AUTOSAR XML (schema 4-0-3)
standard types defined: Boolean, UInt16
package /AUTOSAR_Platform/DataConstrs
  range DC_Boolean: raw 0..1
  range DC_UInt16: raw 0..65535
package /PATAC/MSM/ComponentTypes
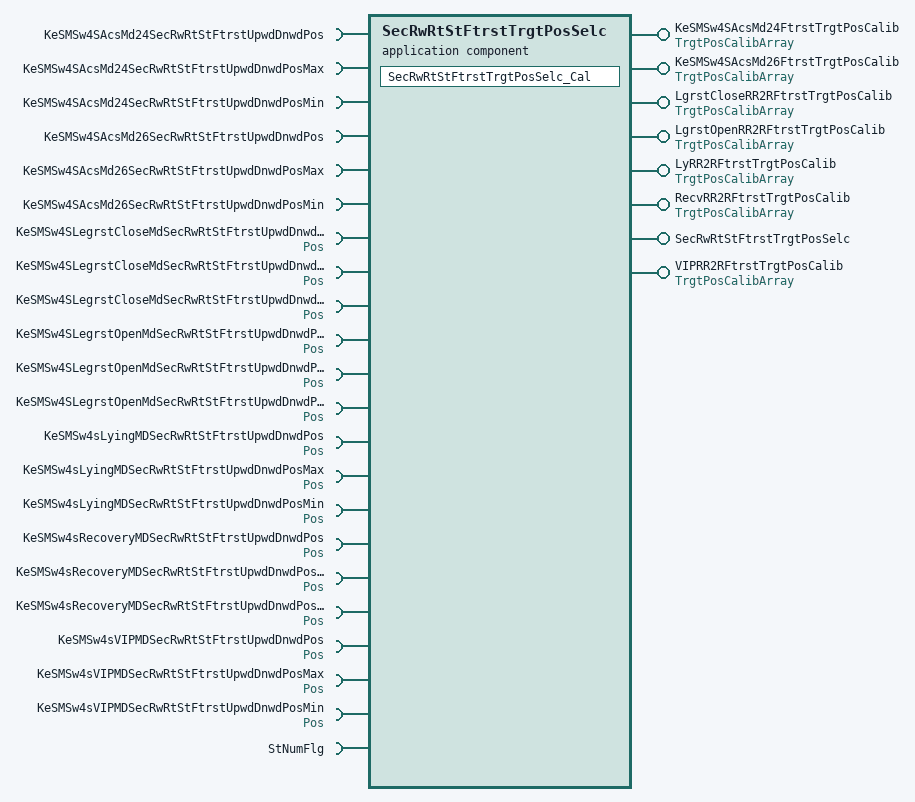
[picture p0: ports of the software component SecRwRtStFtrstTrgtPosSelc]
  application sw component type SecRwRtStFtrstTrgtPosSelc
    8 x provide port:
      KeSMSw4SAcsMd24FtrstTrgtPosCalib: nonqueued-sender-com-spec{data-element=TrgtPosArray, init-value=[4095, 4095, 4095]}, provided-interface=TrgtPosCalibArray
      KeSMSw4SAcsMd26FtrstTrgtPosCalib: nonqueued-sender-com-spec{data-element=TrgtPosArray, init-value=[4095, 4095, 4095]}, provided-interface=TrgtPosCalibArray
      LgrstCloseRR2RFtrstTrgtPosCalib: nonqueued-sender-com-spec{data-element=TrgtPosArray, init-value=[4095, 4095, 4095]}, provided-interface=TrgtPosCalibArray
      LgrstOpenRR2RFtrstTrgtPosCalib: nonqueued-sender-com-spec{data-element=TrgtPosArray, init-value=[4095, 4095, 4095]}, provided-interface=TrgtPosCalibArray
      LyRR2RFtrstTrgtPosCalib: nonqueued-sender-com-spec{data-element=TrgtPosArray, init-value=[4095, 4095, 4095]}, provided-interface=TrgtPosCalibArray
      RecvRR2RFtrstTrgtPosCalib: nonqueued-sender-com-spec{data-element=TrgtPosArray, init-value=[4095, 4095, 4095]}, provided-interface=TrgtPosCalibArray
      SecRwRtStFtrstTrgtPosSelc: server-com-spec{operation=Cal, queue-length=1}, provided-interface=SecRwRtStFtrstTrgtPosSelc
      VIPRR2RFtrstTrgtPosCalib: nonqueued-sender-com-spec{data-element=TrgtPosArray, init-value=[4095, 4095, 4095]}, provided-interface=TrgtPosCalibArray
    22 x require port:
      KeSMSw4SAcsMd24SecRwRtStFtrstUpwdDnwdPos: parameter-require-com-spec{init-value=0, parameter=KeSMSw4SAcsMd24SecRwRtStFtrstUpwdDnwdPos/Val}, required-interface=KeSMSw4SAcsMd24SecRwRtStFtrstUpwdDnwdPos
      KeSMSw4SAcsMd24SecRwRtStFtrstUpwdDnwdPosMax: parameter-require-com-spec{init-value=0, parameter=KeSMSw4SAcsMd24SecRwRtStFtrstUpwdDnwdPosMax/Val}, required-interface=KeSMSw4SAcsMd24SecRwRtStFtrstUpwdDnwdPosMax
      KeSMSw4SAcsMd24SecRwRtStFtrstUpwdDnwdPosMin: parameter-require-com-spec{init-value=0, parameter=KeSMSw4SAcsMd24SecRwRtStFtrstUpwdDnwdPosMin/Val}, required-interface=KeSMSw4SAcsMd24SecRwRtStFtrstUpwdDnwdPosMin
      KeSMSw4SAcsMd26SecRwRtStFtrstUpwdDnwdPos: parameter-require-com-spec{init-value=0, parameter=KeSMSw4SAcsMd26SecRwRtStFtrstUpwdDnwdPos/Val}, required-interface=KeSMSw4SAcsMd26SecRwRtStFtrstUpwdDnwdPos
      KeSMSw4SAcsMd26SecRwRtStFtrstUpwdDnwdPosMax: parameter-require-com-spec{init-value=0, parameter=KeSMSw4SAcsMd26SecRwRtStFtrstUpwdDnwdPosMax/Val}, required-interface=KeSMSw4SAcsMd26SecRwRtStFtrstUpwdDnwdPosMax
      KeSMSw4SAcsMd26SecRwRtStFtrstUpwdDnwdPosMin: parameter-require-com-spec{init-value=0, parameter=KeSMSw4SAcsMd26SecRwRtStFtrstUpwdDnwdPosMin/Val}, required-interface=KeSMSw4SAcsMd26SecRwRtStFtrstUpwdDnwdPosMin
      KeSMSw4SLegrstCloseMdSecRwRtStFtrstUpwdDnwdPos: parameter-require-com-spec{init-value=0, parameter=Pos/Val}, required-interface=Pos
      KeSMSw4SLegrstCloseMdSecRwRtStFtrstUpwdDnwdPosMax: parameter-require-com-spec{init-value=0, parameter=Pos/Val}, required-interface=Pos
      KeSMSw4SLegrstCloseMdSecRwRtStFtrstUpwdDnwdPosMin: parameter-require-com-spec{init-value=0, parameter=Pos/Val}, required-interface=Pos
      KeSMSw4SLegrstOpenMdSecRwRtStFtrstUpwdDnwdPos: parameter-require-com-spec{init-value=0, parameter=Pos/Val}, required-interface=Pos
      KeSMSw4SLegrstOpenMdSecRwRtStFtrstUpwdDnwdPosMax: parameter-require-com-spec{init-value=0, parameter=Pos/Val}, required-interface=Pos
      KeSMSw4SLegrstOpenMdSecRwRtStFtrstUpwdDnwdPosMin: parameter-require-com-spec{init-value=0, parameter=Pos/Val}, required-interface=Pos
      KeSMSw4sLyingMDSecRwRtStFtrstUpwdDnwdPos: parameter-require-com-spec{init-value=0, parameter=Pos/Val}, required-interface=Pos
      KeSMSw4sLyingMDSecRwRtStFtrstUpwdDnwdPosMax: parameter-require-com-spec{init-value=0, parameter=Pos/Val}, required-interface=Pos
      KeSMSw4sLyingMDSecRwRtStFtrstUpwdDnwdPosMin: parameter-require-com-spec{init-value=0, parameter=Pos/Val}, required-interface=Pos
      KeSMSw4sRecoveryMDSecRwRtStFtrstUpwdDnwdPos: parameter-require-com-spec{init-value=0, parameter=Pos/Val}, required-interface=Pos
      KeSMSw4sRecoveryMDSecRwRtStFtrstUpwdDnwdPosMax: parameter-require-com-spec{init-value=0, parameter=Pos/Val}, required-interface=Pos
      KeSMSw4sRecoveryMDSecRwRtStFtrstUpwdDnwdPosMin: parameter-require-com-spec{init-value=0, parameter=Pos/Val}, required-interface=Pos
      KeSMSw4sVIPMDSecRwRtStFtrstUpwdDnwdPos: parameter-require-com-spec{init-value=0, parameter=Pos/Val}, required-interface=Pos
      KeSMSw4sVIPMDSecRwRtStFtrstUpwdDnwdPosMax: parameter-require-com-spec{init-value=0, parameter=Pos/Val}, required-interface=Pos
      KeSMSw4sVIPMDSecRwRtStFtrstUpwdDnwdPosMin: parameter-require-com-spec{init-value=0, parameter=Pos/Val}, required-interface=Pos
      StNumFlg: required-interface=StNumFlg
        required-com-specs:
          data-element=Is4s, filter=data-filter-type=ALWAYS, init-value=0
          data-element=Is6s, filter=data-filter-type=ALWAYS, init-value=0
          data-element=Is6s7s, filter=data-filter-type=ALWAYS, init-value=0
          data-element=Is7s, filter=data-filter-type=ALWAYS, init-value=0
    behavior SecRwRtStFtrstTrgtPosSelc_InternalBehavior
      operation invoked event OIT_SecRwRtStFtrstTrgtPosSelc_Cal_SecRwRtStFtrstTrgtPosSelc_Cal: start-on-event=SecRwRtStFtrstTrgtPosSelc_Cal, operation=SecRwRtStFtrstTrgtPosSelc.Cal
      runnable SecRwRtStFtrstTrgtPosSelc_Cal
        data-receive-point-by-arguments:
          4 x access:
            REC_StNumFlg_Is4s: accessed-variable=StNumFlg.Is4s
            REC_StNumFlg_Is6s: accessed-variable=StNumFlg.Is6s
            REC_StNumFlg_Is6s7s: accessed-variable=StNumFlg.Is6s7s
            REC_StNumFlg_Is7s: accessed-variable=StNumFlg.Is7s
        data-send-points:
          7 x access:
            SEND_KeSMSw4SAcsMd24FtrstTrgtPosCalib_TrgtPosArray: accessed-variable=KeSMSw4SAcsMd24FtrstTrgtPosCalib.TrgtPosArray
            SEND_KeSMSw4SAcsMd26FtrstTrgtPosCalib_TrgtPosArray: accessed-variable=KeSMSw4SAcsMd26FtrstTrgtPosCalib.TrgtPosArray
            SEND_LgrstCloseRR2RFtrstTrgtPosCalib_TrgtPosArray: accessed-variable=LgrstCloseRR2RFtrstTrgtPosCalib.TrgtPosArray
            SEND_LgrstOpenRR2RFtrstTrgtPosCalib_TrgtPosArray: accessed-variable=LgrstOpenRR2RFtrstTrgtPosCalib.TrgtPosArray
            SEND_LyRR2RFtrstTrgtPosCalib_TrgtPosArray: accessed-variable=LyRR2RFtrstTrgtPosCalib.TrgtPosArray
            SEND_RecvRR2RFtrstTrgtPosCalib_TrgtPosArray: accessed-variable=RecvRR2RFtrstTrgtPosCalib.TrgtPosArray
            SEND_VIPRR2RFtrstTrgtPosCalib_TrgtPosArray: accessed-variable=VIPRR2RFtrstTrgtPosCalib.TrgtPosArray
        21 x parameter access:
          PA_KeSMSw4SAcsMd24SecRwRtStFtrstUpwdDnwdPos_Val: accessed-parameter=KeSMSw4SAcsMd24SecRwRtStFtrstUpwdDnwdPos.Val
          PA_KeSMSw4SAcsMd24SecRwRtStFtrstUpwdDnwdPosMax_Val: accessed-parameter=KeSMSw4SAcsMd24SecRwRtStFtrstUpwdDnwdPosMax.Val
          PA_KeSMSw4SAcsMd24SecRwRtStFtrstUpwdDnwdPosMin_Val: accessed-parameter=KeSMSw4SAcsMd24SecRwRtStFtrstUpwdDnwdPosMin.Val
          PA_KeSMSw4SAcsMd26SecRwRtStFtrstUpwdDnwdPos_Val: accessed-parameter=KeSMSw4SAcsMd26SecRwRtStFtrstUpwdDnwdPos.Val
          PA_KeSMSw4SAcsMd26SecRwRtStFtrstUpwdDnwdPosMax_Val: accessed-parameter=KeSMSw4SAcsMd26SecRwRtStFtrstUpwdDnwdPosMax.Val
          PA_KeSMSw4SAcsMd26SecRwRtStFtrstUpwdDnwdPosMin_Val: accessed-parameter=KeSMSw4SAcsMd26SecRwRtStFtrstUpwdDnwdPosMin.Val
          PA_KeSMSw4SLegrstCloseMdSecRwRtStFtrstUpwdDnwdPos_Val: accessed-parameter=KeSMSw4SLegrstCloseMdSecRwRtStFtrstUpwdDnwdPos.Val
          PA_KeSMSw4SLegrstCloseMdSecRwRtStFtrstUpwdDnwdPosMax_Val: accessed-parameter=KeSMSw4SLegrstCloseMdSecRwRtStFtrstUpwdDnwdPosMax.Val
          PA_KeSMSw4SLegrstCloseMdSecRwRtStFtrstUpwdDnwdPosMin_Val: accessed-parameter=KeSMSw4SLegrstCloseMdSecRwRtStFtrstUpwdDnwdPosMin.Val
          PA_KeSMSw4SLegrstOpenMdSecRwRtStFtrstUpwdDnwdPos_Val: accessed-parameter=KeSMSw4SLegrstOpenMdSecRwRtStFtrstUpwdDnwdPos.Val
          PA_KeSMSw4SLegrstOpenMdSecRwRtStFtrstUpwdDnwdPosMax_Val: accessed-parameter=KeSMSw4SLegrstOpenMdSecRwRtStFtrstUpwdDnwdPosMax.Val
          PA_KeSMSw4SLegrstOpenMdSecRwRtStFtrstUpwdDnwdPosMin_Val: accessed-parameter=KeSMSw4SLegrstOpenMdSecRwRtStFtrstUpwdDnwdPosMin.Val
          PA_KeSMSw4sLyingMDSecRwRtStFtrstUpwdDnwdPos_Val: accessed-parameter=KeSMSw4sLyingMDSecRwRtStFtrstUpwdDnwdPos.Val
          PA_KeSMSw4sLyingMDSecRwRtStFtrstUpwdDnwdPosMax_Val: accessed-parameter=KeSMSw4sLyingMDSecRwRtStFtrstUpwdDnwdPosMax.Val
          PA_KeSMSw4sLyingMDSecRwRtStFtrstUpwdDnwdPosMin_Val: accessed-parameter=KeSMSw4sLyingMDSecRwRtStFtrstUpwdDnwdPosMin.Val
          PA_KeSMSw4sRecoveryMDSecRwRtStFtrstUpwdDnwdPos_Val: accessed-parameter=KeSMSw4sRecoveryMDSecRwRtStFtrstUpwdDnwdPos.Val
          PA_KeSMSw4sRecoveryMDSecRwRtStFtrstUpwdDnwdPosMax_Val: accessed-parameter=KeSMSw4sRecoveryMDSecRwRtStFtrstUpwdDnwdPosMax.Val
          PA_KeSMSw4sRecoveryMDSecRwRtStFtrstUpwdDnwdPosMin_Val: accessed-parameter=KeSMSw4sRecoveryMDSecRwRtStFtrstUpwdDnwdPosMin.Val
          PA_KeSMSw4sVIPMDSecRwRtStFtrstUpwdDnwdPos_Val: accessed-parameter=KeSMSw4sVIPMDSecRwRtStFtrstUpwdDnwdPos.Val
          PA_KeSMSw4sVIPMDSecRwRtStFtrstUpwdDnwdPosMax_Val: accessed-parameter=KeSMSw4sVIPMDSecRwRtStFtrstUpwdDnwdPosMax.Val
          PA_KeSMSw4sVIPMDSecRwRtStFtrstUpwdDnwdPosMin_Val: accessed-parameter=KeSMSw4sVIPMDSecRwRtStFtrstUpwdDnwdPosMin.Val
  swc implementation SecRwRtStFtrstTrgtPosSelc_Implementation: behavior=SecRwRtStFtrstTrgtPosSelc_InternalBehavior
    code-descriptors:
      code Default: artifact-descriptors=autosar-engineering-object={short-label=Default, category=SWSRC}
package /PATAC/MSM/ModeAdjust/CalPortInterface
  7 x parameter interface:
    KeSMSw4SAcsMd24SecRwRtStFtrstUpwdDnwdPos
      parameter data prototype Val: sw-calibration-access=READ-WRITE, type=UInt16
    KeSMSw4SAcsMd24SecRwRtStFtrstUpwdDnwdPosMax
      parameter data prototype Val: sw-calibration-access=READ-WRITE, type=UInt16
    KeSMSw4SAcsMd24SecRwRtStFtrstUpwdDnwdPosMin
      parameter data prototype Val: sw-calibration-access=READ-WRITE, type=UInt16
    KeSMSw4SAcsMd26SecRwRtStFtrstUpwdDnwdPos
      parameter data prototype Val: sw-calibration-access=READ-WRITE, type=UInt16
    KeSMSw4SAcsMd26SecRwRtStFtrstUpwdDnwdPosMax
      parameter data prototype Val: sw-calibration-access=READ-WRITE, type=UInt16
    KeSMSw4SAcsMd26SecRwRtStFtrstUpwdDnwdPosMin
      parameter data prototype Val: sw-calibration-access=READ-WRITE, type=UInt16
    Pos
      parameter data prototype Val: sw-calibration-access=READ-WRITE, type=UInt16
package /PATAC/MSM/ModeAdjust/DataType
  impl type TrgtPosCalibArray: category=ARRAY, sw-calibration-access=READ-ONLY, type-emitter=RTE  # 0:pos 1:max 2:min
    element Element: array-size=3, array-size-semantics=FIXED-SIZE, implementation-data-type=UInt16, invalid-value=0
package /PATAC/MSM/ModeAdjust/PortInterface
  client server interface SecRwRtStFtrstTrgtPosSelc
    operation Cal
  sender receiver interface StNumFlg
    4 x data, all with type=Boolean:
      Is4s
      Is6s
      Is6s7s
      Is7s
    invalidation-policys:
      data-element=Is7s, handle-invalid=DONT-INVALIDATE
      data-element=Is6s, handle-invalid=DONT-INVALIDATE
      data-element=Is4s, handle-invalid=DONT-INVALIDATE
      data-element=Is6s7s, handle-invalid=DONT-INVALIDATE
  sender receiver interface TrgtPosCalibArray: invalidation-policy{data-element=TrgtPosArray, handle-invalid=DONT-INVALIDATE}
    data TrgtPosArray: type=TrgtPosCalibArray  # 0:Pos 1:Max 2:Min
